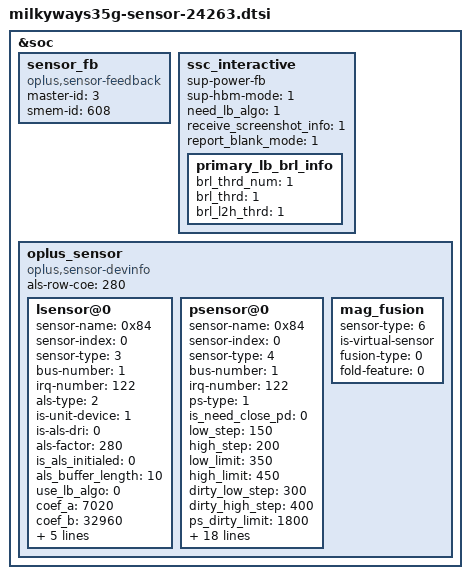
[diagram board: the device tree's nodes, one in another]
/**********************************************************************************
  * Copyright (c)  2022-2024  Guangdong oplus Mobile Comm Corp., Ltd
  * Description: oplus sensor dtsi
  *
  * Version: 1.0
  * Date: 2022-07-04
  *
  * ------------------------------ Revision History: --------------------------------
  * <version>         <date>        <author>                <desc>
  ***********************************************************************************/

&soc {
    //#ifdef OPLUS_FEATURE_SENSOR_SMEM
	sensor_fb: sensor_fb {
		compatible = "oplus,sensor-feedback";
		master-id  = <3>;
		smem-id    = <608>;
	};
	ssc_interactive {
		sup-power-fb;
		sup-hbm-mode = <1>;
		need_lb_algo = <1>;
		receive_screenshot_info = <1>;
		report_blank_mode = <1>;

		primary_lb_brl_info {
			brl_thrd_num = <1>;
			brl_thrd = <1>;
			brl_l2h_thrd = <1>;
		};
	};
	oplus_sensor {
		compatible = "oplus,sensor-devinfo";
		als-row-coe = <280>;
		/*enum {STK3A5X=0x01,TCS3701=0x02,TCS3408=0x04,STK3A6X=0x08};*/
		lsensor@0 {
			sensor-name = <0x84>;//STK6A7X
			sensor-index = <0>;
			sensor-type = <3>;//OPLUS_ALS
			bus-number = <1>;
			irq-number = <122>;
			als-type = <2>;//UNDER_LCD
			is-unit-device = <1>;
			is-als-dri = <0>;
			als-factor = <280>;
			is_als_initialed = <0>;
			als_buffer_length = <10>;
			//normalization_value = <549>;
			use_lb_algo = <0>;
			coef_a     = <7020>;
			coef_b     = <32960>;
			coef_c     = <1536>;
			coef_d     = <6320>;
			coef_e     = <2500>;
			coef_ratio = <13000>;
			lcd_name = "P_4";

		};
		psensor@0 {
			sensor-name = <0x84>;//STK6A7X
			sensor-index = <0>;
			sensor-type = <4>;//OPLUS_PROXIMITY
			bus-number = <1>;
			irq-number = <122>;
			//ps-cail-type = <2>;
			ps-type = <1>;
			/*1-need close 2-close has contidition 0-not close*/
			is_need_close_pd = <0>;
			//is_ps_initialzed = <0>;
			low_step = <150>;
			high_step = <200>;
			low_limit = <350>;
			high_limit = <450>;
			dirty_low_step = <300>;
			dirty_high_step = <400>;
			ps_dirty_limit = <1800>;
			ps_ir_limit = <2000>;
			ps_adjust_min = <0>;
			ps_adjust_max = <1850>;
			sampling_count = <5>;
			step_max = <400>;
			step_min = <100>;
			step_div = <2000>;
			anti_shake_delta = <70>;
			dynamic_cali_max = <2000>;
			raw2offset_radio = <1000>;
			offset_max = <60000>;
			offset_range_min = <0>;
			offset_range_max = <65534>;
			force_cali_limit = <2000>;
			cali_jitter_limit = <20>;
			cal_offset_margin = <3000>;
			parameter-number = <6>;
			sensor-reg = <0x05 0x20
					0x02 0x73
					0x03 0x2C>;
		};
		/*virtual sensor*/
		mag_fusion {
			sensor-type = <6>;//OPLUS_MAG_FUSION
			is-virtual-sensor;
			fusion-type = <0>;//AKM_FUSION
			fold-feature = <0>;
		};
	};
	//#endif /*OPLUS_FEATURE_SENSOR_SMEM*/
};

